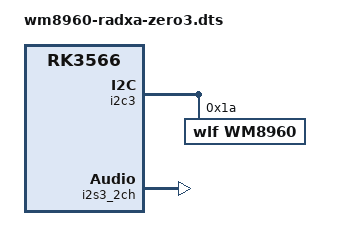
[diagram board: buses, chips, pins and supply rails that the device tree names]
/*
 * WM8960 Sound Card Device Tree Overlay - Radxa ZERO 3W (RK3566)
 *
 * Features:
 *   - Configure WM8960 codec on I2C3 bus (address 0x1a)
 *   - Enable I2S3 interface (pin mux mode 0)
 *   - Create simple-audio-card sound card
 *
 * 40-pin Header Pin Mapping:
 *   PIN_3  (SDA)  -> I2C3_SDA_M0
 *   PIN_5  (SCL)  -> I2C3_SCL_M0
 *   PIN_12 (BCLK) -> I2S3_SCLK_M0
 *   PIN_35 (LRCK) -> I2S3_LRCK_RX_M0
 *   PIN_38 (SDI)  -> I2S3_SDI_M0
 *   PIN_40 (SDO)  -> I2S3_SDO_M0
 *
 * Compile:
 *   dtc -@ -I dts -O dtb -o wm8960-radxa-zero3.dtbo wm8960-radxa-zero3.dts
 */

/dts-v1/;
/plugin/;

/ {
    compatible = "rockchip,rk3566";

    /* Add WM8960 codec on I2C3 */
    fragment@0 {
        target = <&i2c3>;
        __overlay__ {
            status = "okay";
            #address-cells = <1>;
            #size-cells = <0>;

            wm8960: wm8960@1a {
                compatible = "wlf,wm8960";
                reg = <0x1a>;
                #sound-dai-cells = <0>;
                wlf,shared-lrclk;

                /*
                 * Mainline rk3566 leaves the I2S3 MCLK output gate off, so the
                 * codec gets no master clock and every hw_params fails with
                 * "wm8960 3-001a: No MCLK configured". (The Radxa vendor kernel
                 * the PiSugar installer targets drives MCLK implicitly, which is
                 * why the same DTS works there.) Mirror rk3566-roc-pc.dts: hand
                 * the codec the I2S3 MCLK and route+enable the output gate.
                 *
                 * Numeric IDs because the overlay is compiled without the kernel
                 * dt-bindings include path:
                 *   I2S3_MCLKOUT_TX = 84, CLK_I2S3_2CH_TX = 409  (rk3568-cru.h)
                 */
                clocks = <&cru 84>;
                clock-names = "mclk";
                assigned-clocks = <&cru 84>;
                assigned-clock-parents = <&cru 409>;
            };
        };
    };

    /* Enable I2S3 audio interface */
    fragment@1 {
        target = <&i2s3_2ch>;
        __overlay__ {
            status = "okay";
            /*
             * Full-duplex on one I2S with a shared LRCLK: RX must reuse TX's
             * BCLK/LRCK. The MAINLINE rockchip-i2s-tdm driver spells this
             * `rockchip,trcm-sync-tx-only` (boolean); the vendor kernel's
             * `rockchip,clk-trcm = <1>` is a different name the mainline driver
             * ignores — which left capture with no clock and made arecord fail
             * with "hw_params ... -22". Only TX clock pins are routed below, so
             * tx-only sync is required for the mic to work.
             */
            rockchip,trcm-sync-tx-only;
            pinctrl-names = "default";
            /*
             * MCLK pin is essential: the WM8960 has no crystal, so it needs the
             * SoC to drive a master clock. Enabling I2S3_MCLKOUT_TX in the CRU
             * (codec `clocks`/`assigned-clocks`) is not enough — without muxing
             * i2s3m0_mclk to the header pin, MCLK never physically reaches the
             * codec, so the DAC runs silent even though the driver/DAPM look OK.
             */
            pinctrl-0 = <&i2s3m0_mclk
                         &i2s3m0_sclk
                         &i2s3m0_lrck
                         &i2s3m0_sdi
                         &i2s3m0_sdo>;
        };
    };

    /* Create WM8960 sound card */
    fragment@2 {
        target-path = "/";
        __overlay__ {
            wm8960_sound: wm8960-sound {
                status = "okay";
                compatible = "simple-audio-card";
                simple-audio-card,name = "wm8960-soundcard";
                simple-audio-card,format = "i2s";
                simple-audio-card,mclk-fs = <256>;

                simple-audio-card,widgets =
                    "Microphone", "Mic Jack",
                    "Speaker", "Speaker",
                    "Headphone", "Headphone Jack";

                simple-audio-card,routing =
                    "Headphone Jack", "HP_L",
                    "Headphone Jack", "HP_R",
                    "Speaker", "SPK_LP",
                    "Speaker", "SPK_LN",
                    "Speaker", "SPK_RP",
                    "Speaker", "SPK_RN",
                    "LINPUT1", "Mic Jack",
                    "RINPUT1", "Mic Jack";

                simple-audio-card,cpu {
                    sound-dai = <&i2s3_2ch>;
                };

                simple-audio-card,codec {
                    sound-dai = <&wm8960>;
                };
            };
        };
    };
};
